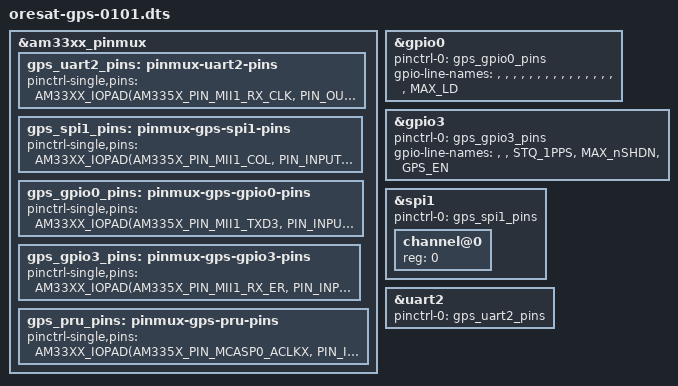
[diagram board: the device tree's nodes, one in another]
/* OreSat GPS v1.1 device tree */

/dts-v1/;

#include "oresat-base.dtsi"

&am33xx_pinmux {
  /* skytraq */
  gps_uart2_pins: pinmux-uart2-pins {
    pinctrl-single,pins = <
      AM33XX_IOPAD(AM335X_PIN_MII1_RX_CLK, PIN_OUTPUT_PULLDOWN | MUX_MODE1) /* uart2_txd */
      AM33XX_IOPAD(AM335X_PIN_MII1_TX_CLK, PIN_INPUT_PULLUP | MUX_MODE1) /* uart2_rxd */
    >;
  };

  /* max2771 */
  gps_spi1_pins: pinmux-gps-spi1-pins {
    pinctrl-single,pins = <
      /* 3-wire spi */
      AM33XX_IOPAD(AM335X_PIN_MII1_COL, PIN_INPUT_PULLUP | MUX_MODE2) /* spi1_sclk */
      AM33XX_IOPAD(AM335X_PIN_MII1_CRS, PIN_INPUT_PULLUP | MUX_MODE2) /* spi1_d0 */
      AM33XX_IOPAD(AM335X_PIN_RMII1_REF_CLK, PIN_OUTPUT_PULLUP | MUX_MODE2) /* spi1_cs0 */
    >;
  };

  gps_gpio0_pins: pinmux-gps-gpio0-pins {
    pinctrl-single,pins = <
      AM33XX_IOPAD(AM335X_PIN_MII1_TXD3, PIN_INPUT | MUX_MODE7) /* gpio0_16 / MAX_LD */
    >;
  };

  gps_gpio3_pins: pinmux-gps-gpio3-pins {
    pinctrl-single,pins = <
      /* skytraq orion b16 gpio pins */
      AM33XX_IOPAD(AM335X_PIN_MII1_RX_ER, PIN_INPUT | MUX_MODE7) /* gpio3_2 / STQ_1PPS */

      /* max2771 gpio pins */
      AM33XX_IOPAD(AM335X_PIN_MII1_TX_EN, PIN_OUTPUT | MUX_MODE7) /* gpio3_3 / MAX_nSHDN */

      /* GPS_EN toggles power for the gps section of the card */
      AM33XX_IOPAD(AM335X_PIN_MII1_RX_DV, PIN_OUTPUT | MUX_MODE7) /* gpio3_4 / GPS_EN */
    >;
  };

  gps_pru_pins: pinmux-gps-pru-pins {
    pinctrl-single,pins = <
      /* PRU pins for reading data from the max2771 GNSS Receiver */
      AM33XX_IOPAD(AM335X_PIN_MCASP0_ACLKX, PIN_INPUT | MUX_MODE6) /* pr1_pru0_pru_r31_0 / MAX_I1 */
      AM33XX_IOPAD(AM335X_PIN_MCASP0_AHCLKR, PIN_INPUT | MUX_MODE6) /* pr1_pru0_pru_r31_3 / MAX_Q0 */
      AM33XX_IOPAD(AM335X_PIN_MCASP0_AXR0, PIN_INPUT | MUX_MODE6) /* pr1_pru0_pru_r31_2 / MAX_Q1 */
      AM33XX_IOPAD(AM335X_PIN_MCASP0_FSX, PIN_INPUT | MUX_MODE6) /* pr1_pru0_pru_r31_1 / MAX_I0 */
      AM33XX_IOPAD(AM335X_PIN_XDMA_EVENT_INTR1, PIN_INPUT | MUX_MODE5) /* pr1_pru0_pru_r31_16 / MAX_CLKOUT */
    >;
  };
};

&gpio0 {
  pinctrl-names = "default";
  pinctrl-0 = <&gps_gpio0_pins>;
  gpio-line-names = "", "", "", "", "", "", "", "",
                    "", "", "", "", "", "", "", "",
                    "MAX_LD";
};

&gpio3 {
  pinctrl-names = "default";
  pinctrl-0 = <&gps_gpio3_pins>;
  gpio-line-names = "", "", "STQ_1PPS", "MAX_nSHDN", "GPS_EN";
};


&spi1 {
  status = "okay";
  pinctrl-names = "default";
  pinctrl-0 = <&gps_spi1_pins>;

  channel@0 {
    reg = <0>;
    status = "okay";
  };
};

&uart2 {
  status = "okay";
  pinctrl-names = "default";
  pinctrl-0 = <&gps_uart2_pins>;
};
